VERSION "1.0"

NS_ :

BS_:

BU_: HOST ACT1

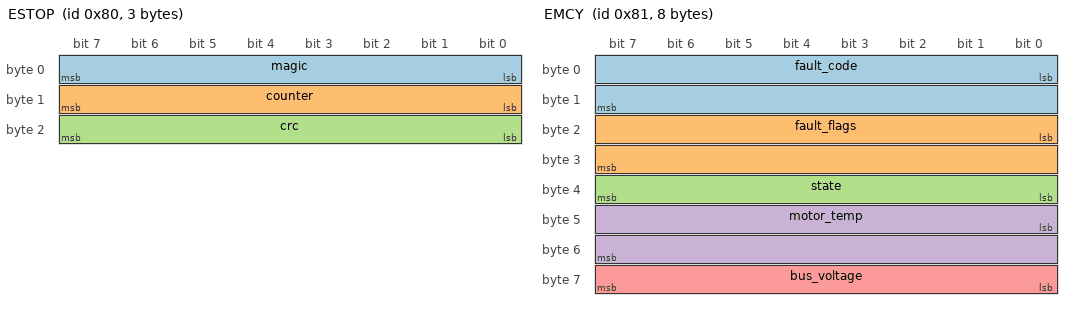
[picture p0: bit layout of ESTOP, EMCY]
BO_ 128 ESTOP: 3 HOST
 SG_ magic : 0|8@1+ (1,0) [0|255] "" ACT1
 SG_ counter : 8|8@1+ (1,0) [0|255] "" ACT1
 SG_ crc : 16|8@1+ (1,0) [0|255] "" ACT1

BO_ 129 EMCY: 8 ACT1
 SG_ fault_code : 0|16@1+ (1,0) [0|65535] "" HOST
 SG_ fault_flags : 16|16@1+ (1,0) [0|65535] "" HOST
 SG_ state : 32|8@1+ (1,0) [0|255] "" HOST
 SG_ motor_temp : 40|16@1- (0.1,0) [-3276.8|3276.7] "degC" HOST
 SG_ bus_voltage : 56|8@1+ (0.5,0) [0|127.5] "V" HOST

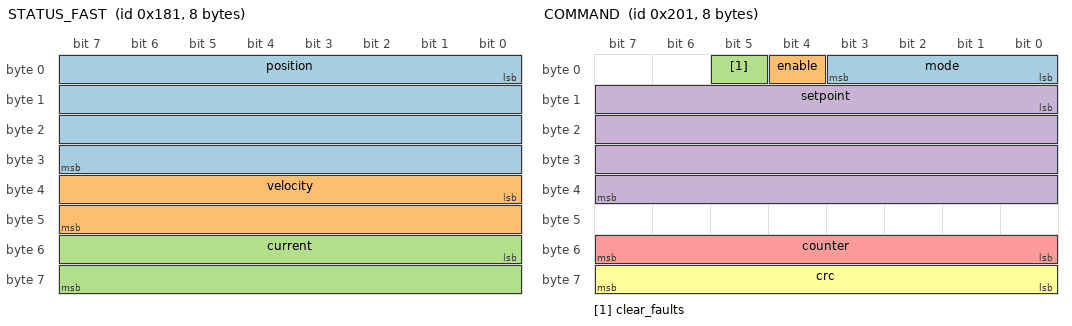
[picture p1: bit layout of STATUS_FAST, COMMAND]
BO_ 385 STATUS_FAST: 8 ACT1
 SG_ position : 0|32@1- (0.0001,0) [-214748.3648|214748.3647] "rad" HOST
 SG_ velocity : 32|16@1- (0.001,0) [-32.768|32.767] "rad/s" HOST
 SG_ current : 48|16@1- (0.001,0) [-32.768|32.767] "A" HOST

BO_ 513 COMMAND: 8 HOST
 SG_ mode : 0|4@1+ (1,0) [0|3] "" ACT1
 SG_ enable : 4|1@1+ (1,0) [0|1] "" ACT1
 SG_ clear_faults : 5|1@1+ (1,0) [0|1] "" ACT1
 SG_ setpoint : 8|32@1- (0.0001,0) [-214748.3648|214748.3647] "" ACT1
 SG_ counter : 48|8@1+ (1,0) [0|255] "" ACT1
 SG_ crc : 56|8@1+ (1,0) [0|255] "" ACT1

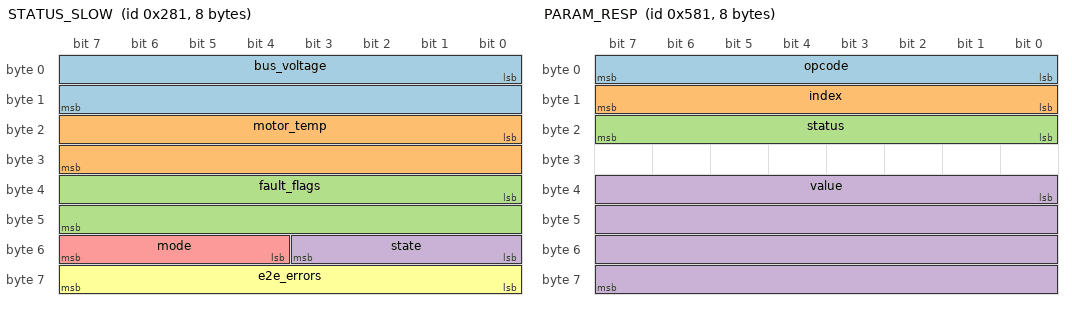
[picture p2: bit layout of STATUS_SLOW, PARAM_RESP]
BO_ 641 STATUS_SLOW: 8 ACT1
 SG_ bus_voltage : 0|16@1+ (0.01,0) [0|655.35] "V" HOST
 SG_ motor_temp : 16|16@1- (0.1,0) [-3276.8|3276.7] "degC" HOST
 SG_ fault_flags : 32|16@1+ (1,0) [0|65535] "" HOST
 SG_ state : 48|4@1+ (1,0) [0|15] "" HOST
 SG_ mode : 52|4@1+ (1,0) [0|15] "" HOST
 SG_ e2e_errors : 56|8@1+ (1,0) [0|255] "" HOST

BO_ 1409 PARAM_RESP: 8 ACT1
 SG_ opcode : 0|8@1+ (1,0) [0|255] "" HOST
 SG_ index : 8|8@1+ (1,0) [0|255] "" HOST
 SG_ status : 16|8@1+ (1,0) [0|255] "" HOST
 SG_ value : 32|32@1- (1,0) [-3.4E+038|3.4E+038] "" HOST

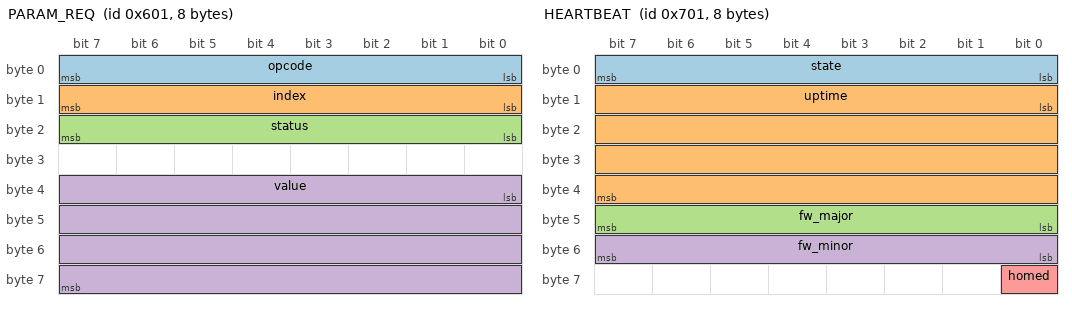
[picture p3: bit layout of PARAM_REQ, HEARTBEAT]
BO_ 1537 PARAM_REQ: 8 HOST
 SG_ opcode : 0|8@1+ (1,0) [0|255] "" ACT1
 SG_ index : 8|8@1+ (1,0) [0|255] "" ACT1
 SG_ status : 16|8@1+ (1,0) [0|255] "" ACT1
 SG_ value : 32|32@1- (1,0) [-3.4E+038|3.4E+038] "" ACT1

BO_ 1793 HEARTBEAT: 8 ACT1
 SG_ state : 0|8@1+ (1,0) [0|255] "" HOST
 SG_ uptime : 8|32@1+ (0.001,0) [0|4294967.295] "s" HOST
 SG_ fw_major : 40|8@1+ (1,0) [0|255] "" HOST
 SG_ fw_minor : 48|8@1+ (1,0) [0|255] "" HOST
 SG_ homed : 56|1@1+ (1,0) [0|1] "" HOST

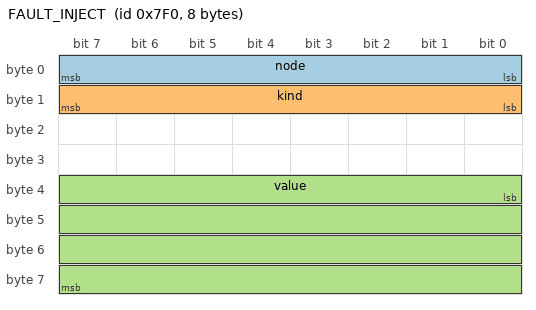
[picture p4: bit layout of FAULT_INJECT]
BO_ 2032 FAULT_INJECT: 8 HOST
 SG_ node : 0|8@1+ (1,0) [0|255] "" ACT1
 SG_ kind : 8|8@1+ (1,0) [0|255] "" ACT1
 SG_ value : 32|32@1- (1,0) [-3.4E+038|3.4E+038] "" ACT1

CM_ "Smart actuator CAN interface. Classic CAN, 500 kbit/s, 11-bit IDs. Every ID except ESTOP and FAULT_INJECT is a function code plus the node ID (CANopen style): the messages below are written for node 1, and node n uses the same layout at ID = function code + n.";
CM_ BO_ 128 "Broadcast emergency stop from the host, the highest-priority frame on the bus. Every node disables its output and latches the ESTOP fault. crc = CRC-8 SAE J1850 over the two ID bytes (low, high) and bytes 0-1.";
CM_ BO_ 129 "Sent once when a node latches new faults. fault_code = the bits newly set, fault_flags = all latched faults.";
CM_ BO_ 385 "Fast status at 100 Hz. Joint-side position, velocity and current.";
CM_ BO_ 513 "Command from the host at 50-100 Hz. The node faults with CMD_TIMEOUT if no valid command arrives for cmd_timeout_ms while enabled. crc = CRC-8 SAE J1850 over the two ID bytes and bytes 0-6; counter must change every frame.";
CM_ SG_ 513 setpoint "Units depend on mode: A (CURRENT), rad/s (VELOCITY), rad (POSITION).";
CM_ BO_ 641 "Slow status at 10 Hz.";
CM_ SG_ 641 e2e_errors "Commands dropped for a bad CRC, wrong length or repeated counter (saturates at 255).";
CM_ BO_ 1409 "Parameter response. status: 0 OK, 1 bad index, 2 read-only, 3 out of range, 4 not allowed while enabled, 5 bad opcode, 6 storage error.";
CM_ BO_ 1537 "Parameter request. opcode: 1 read, 2 write, 3 save to flash, 4 load defaults.";
CM_ BO_ 1793 "Heartbeat at 2 Hz.";
CM_ BO_ 2032 "Simulator test hook. kind: 0 clear all, 1 overheat (W of extra heat), 2 undervoltage (supply V), 3 encoder glitch (rad jump), 4 jam (Nm of friction), 5 current-sensor noise (A std), 6 drop fast status (seconds).";
SIG_VALTYPE_ 1409 value : 1;
SIG_VALTYPE_ 1537 value : 1;
SIG_VALTYPE_ 2032 value : 1;
VAL_ 129 state 0 "BOOT" 1 "DISABLED" 2 "ENABLED" 3 "FAULT" ;
VAL_ 513 mode 0 "IDLE" 1 "CURRENT" 2 "VELOCITY" 3 "POSITION" ;
VAL_ 641 state 0 "BOOT" 1 "DISABLED" 2 "ENABLED" 3 "FAULT" ;
VAL_ 641 mode 0 "IDLE" 1 "CURRENT" 2 "VELOCITY" 3 "POSITION" ;
VAL_ 1793 state 0 "BOOT" 1 "DISABLED" 2 "ENABLED" 3 "FAULT" ;
